# f29h85x_ssu_cpu2_ap_regs register map
Vendor: Texas Instruments
Peripheral module from a debugger description file (folder C29).
Registers are 32-bit, read-write, no defined reset value unless marked. A register's access mark holds for its fields unless they carry their own. Offsets are as the file gives them; lines under a group give offsets from that group; [hi:lo] are bit positions; {n}, {i} and the like mark numbered series; 'fields as' and 'values as' point back to an identical list; <NAME> marks a mode.

## SSU_CPU2_AP_REGS — SSU CPU2 AP Registers
{0x0+0x20*i} SSU_CPU2_AP_REGS_RegisterFile0[{i}] (i=0..63) group
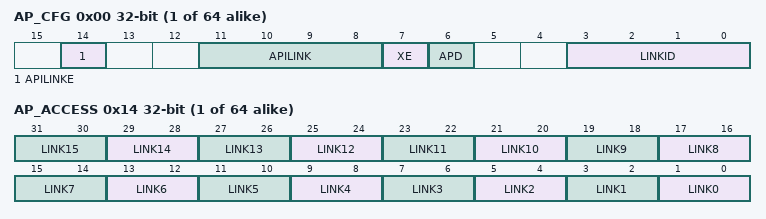
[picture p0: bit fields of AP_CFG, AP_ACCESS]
  0x00 AP_CFG — Access Protection Configuration
    [14] APILINKE — Access Protection Inheritance LINK Enable
    [11:8] APILINK — Access Protection Inheritance LINK
    [7] XE — Execute Enable
    [6] APD — Access Protection Disable
    [3:0] LINKID — LINK ID Value
  0x04 AP_START access not given — Access Protection Start Address
  0x08 AP_END access not given — Access Protection End Address
  0x0C AP_LOCK — Access Protection Temporary Lock
    [0] LOCK — Temporary Lock
  0x10 AP_COMMIT — Access Protection Permanent Commit
    [0] COMMIT — Permanent Commit
  0x14 AP_ACCESS — Access Protection R/W Access Permissions
    [2n+1:2n] LINK{n} (n=0..15) — LINK{n} Access Permissions
